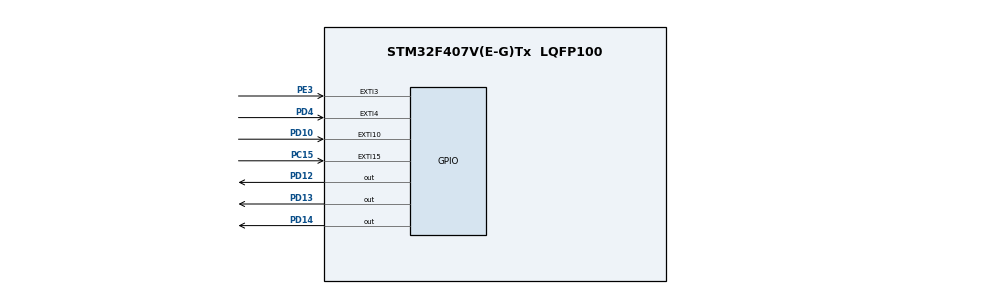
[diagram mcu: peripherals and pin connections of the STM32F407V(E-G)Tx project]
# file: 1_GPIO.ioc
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Mcu.Family=STM32F4
Mcu.Name=STM32F407V(E-G)Tx
Mcu.Package=LQFP100
NVIC.EXTI15_10_IRQn=true\:0\:0\:false\:false\:true\:true\:true\:true
NVIC.EXTI3_IRQn=true\:0\:0\:false\:false\:true\:true\:true\:true
NVIC.EXTI4_IRQn=true\:0\:0\:false\:false\:true\:true\:true\:true
NVIC.PriorityGroup=NVIC_PRIORITYGROUP_4
PC15-OSC32_OUT.Signal=GPXTI15
PD10.Signal=GPXTI10
PD12.Signal=GPIO_Output
PD13.Signal=GPIO_Output
PD14.Signal=GPIO_Output
PD4.Signal=GPXTI4
PE3.Signal=GPXTI3
PH0-OSC_IN.Mode=HSE-External-Oscillator
PH0-OSC_IN.Signal=RCC_OSC_IN
PH1-OSC_OUT.Mode=HSE-External-Oscillator
PH1-OSC_OUT.Signal=RCC_OSC_OUT
ProjectManager.HeapSize=0x200
ProjectManager.StackSize=0x400
ProjectManager.TargetToolchain=CMake
RCC.48MHZClocksFreq_Value=84000000
RCC.AHBFreq_Value=168000000
RCC.APB1CLKDivider=RCC_HCLK_DIV4
RCC.APB1Freq_Value=42000000
RCC.APB1TimFreq_Value=84000000
RCC.APB2CLKDivider=RCC_HCLK_DIV2
RCC.APB2Freq_Value=84000000
RCC.APB2TimFreq_Value=168000000
RCC.CortexFreq_Value=168000000
RCC.HCLKFreq_Value=168000000
RCC.HSE_VALUE=8000000
RCC.HSI_VALUE=16000000
RCC.LSE_VALUE=32768
RCC.PLLM=4
RCC.PLLN=168
RCC.PLLSourceVirtual=RCC_PLLSOURCE_HSE
RCC.SYSCLKFreq_VALUE=168000000
RCC.SYSCLKSource=RCC_SYSCLKSOURCE_PLLCLK
RCC.VCOOutputFreq_Value=336000000
board=custom

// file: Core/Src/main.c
/* USER CODE BEGIN Header */
/**
 ******************************************************************************
 * @file           : main.c
 * @brief          : Main program body
 ******************************************************************************
 * @attention
 *
 * Copyright (c) 2024 STMicroelectronics.
 * All rights reserved.
 *
 * This software is licensed under terms that can be found in the LICENSE file
 * in the root directory of this software component.
 * If no LICENSE file comes with this software, it is provided AS-IS.
 *
 ******************************************************************************
 */
/* USER CODE END Header */
#include "main.h"

void SystemClock_Config(void);
static void MX_GPIO_Init(void);

int main(void) {

  /* MCU Configuration--------------------------------------------------------*/

  /* Reset of all peripherals, Initializes the Flash interface and the Systick.
   */
  LL_APB2_GRP1_EnableClock(LL_APB2_GRP1_PERIPH_SYSCFG);
  LL_APB1_GRP1_EnableClock(LL_APB1_GRP1_PERIPH_PWR);

  /* System interrupt init*/
  NVIC_SetPriorityGrouping(NVIC_PRIORITYGROUP_4);

  /* SysTick_IRQn interrupt configuration */
  NVIC_SetPriority(SysTick_IRQn,
                   NVIC_EncodePriority(NVIC_GetPriorityGrouping(), 15, 0));

  /* Configure the system clock */
  SystemClock_Config();

  /* Initialize all configured peripherals */
  MX_GPIO_Init();
  /* USER CODE BEGIN 2 */
  //= Set => LED off, Reset => LED on
  LL_GPIO_SetOutputPin(GPIOD, LL_GPIO_PIN_12 | LL_GPIO_PIN_13 | LL_GPIO_PIN_14);
  /* USER CODE END 2 */

  /* Infinite loop */
  /* USER CODE BEGIN WHILE */
  uint32_t sw1 = 0x0;
  uint32_t sw2 = 0x0;
  uint32_t output = 0x0 | LL_GPIO_PIN_14;

  while (1) {
    //= GPIO Test first code
    /*sw1 = LL_GPIO_ReadInputPort(GPIOE) & LL_GPIO_PIN_3;
    sw2 = LL_GPIO_ReadInputPort(GPIOC) & LL_GPIO_PIN_15;

    if (sw1) {
      output &= ~LL_GPIO_PIN_12;
    } else {
      output |= LL_GPIO_PIN_12;
    }

    if (sw2) {
      output &= ~LL_GPIO_PIN_13;
    } else {
      output |= LL_GPIO_PIN_13;
    }

    LL_GPIO_WriteOutputPort(GPIOD, output);

    LL_mDelay(250);*/

    //= GPIO Test second code
    //= sw on = 1
    /*sw1 = LL_GPIO_IsInputPinSet(GPIOE, LL_GPIO_PIN_3);
    //= sw on = 0x08 = LL_GPIO_PIN_3
    sw2 = LL_GPIO_ReadInputPort(GPIOE) & LL_GPIO_PIN_3;

    if (sw1) {
      LL_GPIO_TogglePin(GPIOD, LL_GPIO_PIN_12);
      LL_mDelay(50);
      LL_GPIO_TogglePin(GPIOD, LL_GPIO_PIN_12);
      LL_mDelay(50);

      if (LL_GPIO_IsOutputPinSet(GPIOD, LL_GPIO_PIN_13)) {
        LL_GPIO_ResetOutputPin(GPIOD, LL_GPIO_PIN_13);
      } else {
        LL_GPIO_SetOutputPin(GPIOD, LL_GPIO_PIN_13);
      }
    }*/

    //= Third Code is External Interrupt => stm32f4xx_it.c

    /* USER CODE END WHILE */

  }
}

void SystemClock_Config(void) {
  LL_FLASH_SetLatency(LL_FLASH_LATENCY_5);
  while (LL_FLASH_GetLatency() != LL_FLASH_LATENCY_5) {
  }
  LL_PWR_SetRegulVoltageScaling(LL_PWR_REGU_VOLTAGE_SCALE1);
  LL_RCC_HSE_Enable();

  /* Wait till HSE is ready */
  while (LL_RCC_HSE_IsReady() != 1) {
  }
  LL_RCC_PLL_ConfigDomain_SYS(LL_RCC_PLLSOURCE_HSE, LL_RCC_PLLM_DIV_4, 168,
                              LL_RCC_PLLP_DIV_2);
  LL_RCC_PLL_Enable();

  /* Wait till PLL is ready */
  while (LL_RCC_PLL_IsReady() != 1) {
  }
  while (LL_PWR_IsActiveFlag_VOS() == 0) {
  }
  LL_RCC_SetAHBPrescaler(LL_RCC_SYSCLK_DIV_1);
  LL_RCC_SetAPB1Prescaler(LL_RCC_APB1_DIV_4);
  LL_RCC_SetAPB2Prescaler(LL_RCC_APB2_DIV_2);
  LL_RCC_SetSysClkSource(LL_RCC_SYS_CLKSOURCE_PLL);

  /* Wait till System clock is ready */
  while (LL_RCC_GetSysClkSource() != LL_RCC_SYS_CLKSOURCE_STATUS_PLL) {
  }
  LL_Init1msTick(168000000);
  LL_SetSystemCoreClock(168000000);
}

static void MX_GPIO_Init(void) {
  LL_EXTI_InitTypeDef EXTI_InitStruct = {0};
  LL_GPIO_InitTypeDef GPIO_InitStruct = {0};

  /* GPIO Ports Clock Enable */
  LL_AHB1_GRP1_EnableClock(LL_AHB1_GRP1_PERIPH_GPIOE);
  LL_AHB1_GRP1_EnableClock(LL_AHB1_GRP1_PERIPH_GPIOC);
  LL_AHB1_GRP1_EnableClock(LL_AHB1_GRP1_PERIPH_GPIOH);
  LL_AHB1_GRP1_EnableClock(LL_AHB1_GRP1_PERIPH_GPIOD);

  /**/
  LL_GPIO_ResetOutputPin(GPIOD,
                         LL_GPIO_PIN_12 | LL_GPIO_PIN_13 | LL_GPIO_PIN_14);

  /**/
  LL_SYSCFG_SetEXTISource(LL_SYSCFG_EXTI_PORTE, LL_SYSCFG_EXTI_LINE3);

  /**/
  LL_SYSCFG_SetEXTISource(LL_SYSCFG_EXTI_PORTC, LL_SYSCFG_EXTI_LINE15);

  /**/
  LL_SYSCFG_SetEXTISource(LL_SYSCFG_EXTI_PORTD, LL_SYSCFG_EXTI_LINE10);

  /**/
  LL_SYSCFG_SetEXTISource(LL_SYSCFG_EXTI_PORTD, LL_SYSCFG_EXTI_LINE4);

  /**/
  EXTI_InitStruct.Line_0_31 = LL_EXTI_LINE_3;
  EXTI_InitStruct.LineCommand = ENABLE;
  EXTI_InitStruct.Mode = LL_EXTI_MODE_IT;
  EXTI_InitStruct.Trigger = LL_EXTI_TRIGGER_RISING;
  LL_EXTI_Init(&EXTI_InitStruct);

  /**/
  EXTI_InitStruct.Line_0_31 = LL_EXTI_LINE_15;
  EXTI_InitStruct.LineCommand = ENABLE;
  EXTI_InitStruct.Mode = LL_EXTI_MODE_IT;
  EXTI_InitStruct.Trigger = LL_EXTI_TRIGGER_RISING;
  LL_EXTI_Init(&EXTI_InitStruct);

  /**/
  EXTI_InitStruct.Line_0_31 = LL_EXTI_LINE_10;
  EXTI_InitStruct.LineCommand = ENABLE;
  EXTI_InitStruct.Mode = LL_EXTI_MODE_IT;
  EXTI_InitStruct.Trigger = LL_EXTI_TRIGGER_RISING;
  LL_EXTI_Init(&EXTI_InitStruct);

  /**/
  EXTI_InitStruct.Line_0_31 = LL_EXTI_LINE_4;
  EXTI_InitStruct.LineCommand = ENABLE;
  EXTI_InitStruct.Mode = LL_EXTI_MODE_IT;
  EXTI_InitStruct.Trigger = LL_EXTI_TRIGGER_RISING;
  LL_EXTI_Init(&EXTI_InitStruct);

  /**/
  LL_GPIO_SetPinPull(GPIOE, LL_GPIO_PIN_3, LL_GPIO_PULL_NO);

  /**/
  LL_GPIO_SetPinPull(GPIOC, LL_GPIO_PIN_15, LL_GPIO_PULL_NO);

  /**/
  LL_GPIO_SetPinPull(GPIOD, LL_GPIO_PIN_10, LL_GPIO_PULL_NO);

  /**/
  LL_GPIO_SetPinPull(GPIOD, LL_GPIO_PIN_4, LL_GPIO_PULL_NO);

  /**/
  LL_GPIO_SetPinMode(GPIOE, LL_GPIO_PIN_3, LL_GPIO_MODE_INPUT);

  /**/
  LL_GPIO_SetPinMode(GPIOC, LL_GPIO_PIN_15, LL_GPIO_MODE_INPUT);

  /**/
  LL_GPIO_SetPinMode(GPIOD, LL_GPIO_PIN_10, LL_GPIO_MODE_INPUT);

  /**/
  LL_GPIO_SetPinMode(GPIOD, LL_GPIO_PIN_4, LL_GPIO_MODE_INPUT);

  /**/
  GPIO_InitStruct.Pin = LL_GPIO_PIN_12 | LL_GPIO_PIN_13 | LL_GPIO_PIN_14;
  GPIO_InitStruct.Mode = LL_GPIO_MODE_OUTPUT;
  GPIO_InitStruct.Speed = LL_GPIO_SPEED_FREQ_LOW;
  GPIO_InitStruct.OutputType = LL_GPIO_OUTPUT_PUSHPULL;
  GPIO_InitStruct.Pull = LL_GPIO_PULL_NO;
  LL_GPIO_Init(GPIOD, &GPIO_InitStruct);

  /* EXTI interrupt init*/
  NVIC_SetPriority(EXTI3_IRQn,
                   NVIC_EncodePriority(NVIC_GetPriorityGrouping(), 0, 0));
  NVIC_EnableIRQ(EXTI3_IRQn);
  NVIC_SetPriority(EXTI4_IRQn,
                   NVIC_EncodePriority(NVIC_GetPriorityGrouping(), 0, 0));
  NVIC_EnableIRQ(EXTI4_IRQn);
  NVIC_SetPriority(EXTI15_10_IRQn,
                   NVIC_EncodePriority(NVIC_GetPriorityGrouping(), 0, 0));
  NVIC_EnableIRQ(EXTI15_10_IRQn);

}

void Error_Handler(void) {
  __disable_irq();
  while (1) {
  }
}

#ifdef USE_FULL_ASSERT
/**
 * @brief  Reports the name of the source file and the source line number
 *         where the assert_param error has occurred.
 * @param  file: pointer to the source file name
 * @param  line: assert_param error line source number
 * @retval None
 */
void assert_failed(uint8_t *file, uint32_t line) {
  /* USER CODE BEGIN 6 */
  /* User can add his own implementation to report the file name and line
     number, ex: printf("Wrong parameters value: file %s on line %d\r\n", file,
     line) */
  /* USER CODE END 6 */
}
#endif /* USE_FULL_ASSERT */
